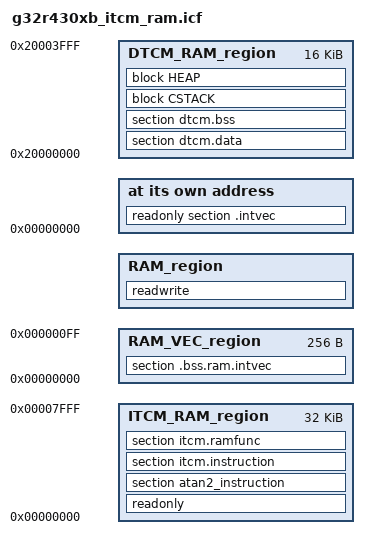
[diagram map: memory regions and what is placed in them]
/*###ICF### Section handled by ICF editor, don't touch! ****/
/*-Editor annotation file-*/
/* IcfEditorFile="$TOOLKIT_DIR$\config\linker\Geehy\IcfEditor\g32r430.xml" */
/*-Specials-*/
define symbol __ICFEDIT_intvec_start__ = 0x00000000;
define symbol __ICFEDIT_intvec_size__ = 0x100;

/*0:DTCM, 1:ITCM, 2:Flash, */
define symbol __vector_region__ = 0x0; 

/*-Memory Regions-*/
define symbol __ICFEDIT_region_FLASH_start__    = 0x0;
define symbol __ICFEDIT_region_FLASH_end__      = 0x0;
define symbol __ICFEDIT_region_ITCM_RAM_start__ = 0x00000000;
define symbol __ICFEDIT_region_ITCM_RAM_end__   = 0x00007FFF;
define symbol __ICFEDIT_region_DTCM_RAM_start__ = 0x20000000;
define symbol __ICFEDIT_region_DTCM_RAM_end__   = 0x20003FFF;

/*-Sizes-*/
define symbol __ICFEDIT_size_cstack__     = 0x1000;
define symbol __ICFEDIT_size_heap__       = 0x200;
/**** End of ICF editor section. ###ICF###*/

define memory mem with size = 4G;
define region FLASH_region    = mem:[from __ICFEDIT_region_FLASH_start__ to __ICFEDIT_region_FLASH_end__];

if (__vector_region__ == 0)
{
define region ITCM_RAM_region = mem:[from __ICFEDIT_region_ITCM_RAM_start__ to __ICFEDIT_region_ITCM_RAM_end__];
define region DTCM_RAM_region = mem:[from (__ICFEDIT_region_DTCM_RAM_start__ + __ICFEDIT_intvec_size__) to __ICFEDIT_region_DTCM_RAM_end__];
define region RAM_VEC_region = mem:[from __ICFEDIT_region_DTCM_RAM_start__  to (__ICFEDIT_region_DTCM_RAM_start__ + __ICFEDIT_intvec_size__ - 1)];
}
else if(__vector_region__ == 1)
{
define region ITCM_RAM_region = mem:[from (__ICFEDIT_region_ITCM_RAM_start__ + __ICFEDIT_intvec_size__) to __ICFEDIT_region_ITCM_RAM_end__];
define region DTCM_RAM_region = mem:[from __ICFEDIT_region_DTCM_RAM_start__ to __ICFEDIT_region_DTCM_RAM_end__];
define region RAM_VEC_region = mem:[from __ICFEDIT_region_ITCM_RAM_start__  to (__ICFEDIT_region_ITCM_RAM_start__ + __ICFEDIT_intvec_size__ - 1)];
}
else
{
define region ITCM_RAM_region = mem:[from __ICFEDIT_region_ITCM_RAM_start__ to __ICFEDIT_region_ITCM_RAM_end__];
define region DTCM_RAM_region = mem:[from __ICFEDIT_region_DTCM_RAM_start__ to __ICFEDIT_region_DTCM_RAM_end__];
}

define region RAM_region = DTCM_RAM_region;

define block CSTACK     with alignment = 8, size = __ICFEDIT_size_cstack__     { };
define block HEAP       with alignment = 8, size = __ICFEDIT_size_heap__       { };

if (__vector_region__ != 2)
{
    do not initialize  { section .noinit, section .bss.ram.intvec};
}
else
{
    do not initialize  { section .noinit};
}

initialize by copy { readwrite,  section dtcm.data};
initialize manually { };

if (isdefinedsymbol(__USE_DLIB_PERTHREAD))
{
  // Required in a multi-threaded application
  initialize by copy with packing = none { section __DLIB_PERTHREAD };
}

place at address mem:__ICFEDIT_intvec_start__ { readonly section .intvec };

place in ITCM_RAM_region  { readonly, section atan2_instruction, section itcm.instruction, section itcm.ramfunc};
place in DTCM_RAM_region  { section dtcm.data, section dtcm.bss, block CSTACK, block HEAP };
place in RAM_region    { readwrite };

if (__vector_region__ != 2)
{
    place in RAM_VEC_region { section .bss.ram.intvec};
}

